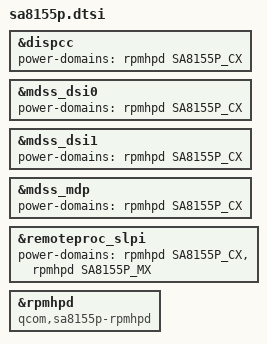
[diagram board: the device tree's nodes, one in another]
#include "sm8150.dtsi"
&dispcc {
	power-domains = <&rpmhpd SA8155P_CX>;
};
&mdss_dsi0 {
	power-domains = <&rpmhpd SA8155P_CX>;
};
&mdss_dsi1 {
	power-domains = <&rpmhpd SA8155P_CX>;
};
&mdss_mdp {
	power-domains = <&rpmhpd SA8155P_CX>;
};
&remoteproc_slpi {
	power-domains = <&rpmhpd SA8155P_CX>,
			<&rpmhpd SA8155P_MX>;
};
&rpmhpd {
	compatible = "qcom,sa8155p-rpmhpd";
};
